# f29h85x_epg_regs register map
Vendor: Texas Instruments
Peripheral module from a debugger description file (folder C29).
Registers are 32-bit, read-write, no defined reset value unless marked. A register's access mark holds for its fields unless they carry their own. Offsets are as the file gives them; lines under a group give offsets from that group; [hi:lo] are bit positions; {n}, {i} and the like mark numbered series; 'fields as' and 'values as' point back to an identical list; <NAME> marks a mode.

## EPG_REGS — EPG Registers
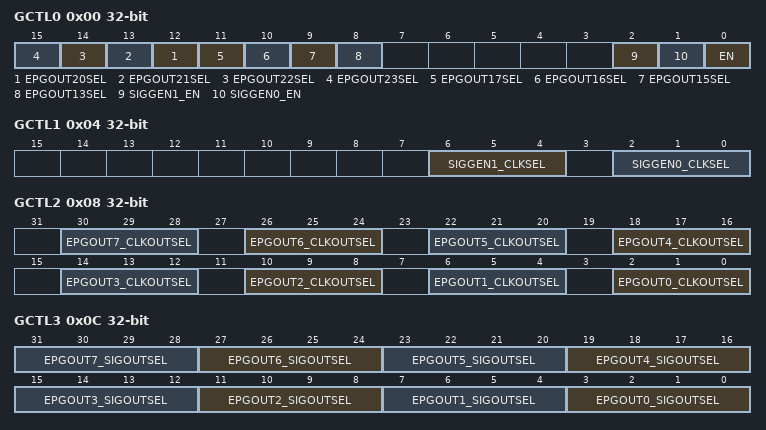
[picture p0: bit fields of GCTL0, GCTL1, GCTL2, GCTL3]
0x00 GCTL0 — EPG Global control register 0
  [n-8] EPGOUT{n}SEL (n=20..23) — EPG output {n} Clock/signal select
  [11] EPGOUT17SEL — EPG output 17 Clock/signal select
  [10] EPGOUT16SEL — EPG output 16 Clock/signal select
  [9] EPGOUT15SEL — EPG output 15 Clock/signal select
  [8] EPGOUT13SEL — EPG output 13 Clock/signal select
  [2] SIGGEN1_EN — Signal generator enable
  [1] SIGGEN0_EN — Signal generator enable
  [0] EN — Enable EPG
0x04 GCTL1 — EPG Global control register 1
  [6:4] SIGGEN1_CLKSEL — Clock source select of SIGGEN1
  [2:0] SIGGEN0_CLKSEL — Clock source select of SIGGEN0
0x08 GCTL2 — EPG Global control register 2
  [4n+2:4n] EPGOUT{n}_CLKOUTSEL (n=0..7) — Selects the clock signal source of EPG output {n}.
0x0C GCTL3 — EPG Global control register 3
  [4n+3:4n] EPGOUT{n}_SIGOUTSEL (n=0..7) — Selects the signal source of EPG output {n}.
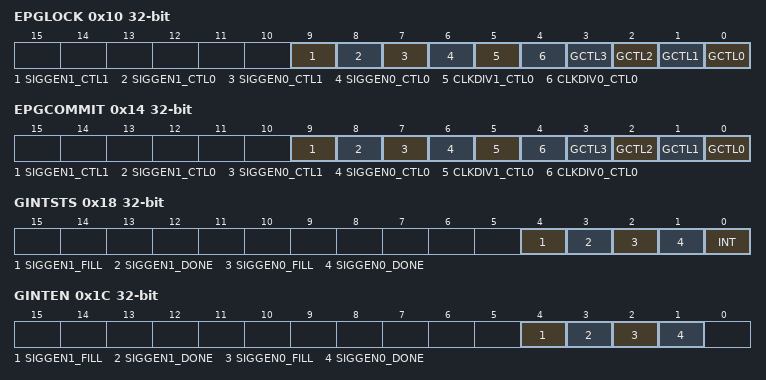
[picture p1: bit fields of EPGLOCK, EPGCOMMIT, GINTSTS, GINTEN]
0x10 EPGLOCK
  [9] SIGGEN1_CTL1 — SIGGEN1_CTL1 Lock bit
  [8] SIGGEN1_CTL0 — SIGGEN1_CTL0 Lock bit
  [7] SIGGEN0_CTL1 — SIGGEN0_CTL1 Lock bit
  [6] SIGGEN0_CTL0 — SIGGEN0_CTL0 Lock bit
  [5] CLKDIV1_CTL0 — CLKDIV1_CTL0 Lock bit
  [4] CLKDIV0_CTL0 — CLKDIV0_CTL0 Lock bit
  [n] GCTL{n} (n=0..3) — GCTL{n} Lock bit
0x14 EPGCOMMIT
  [9] SIGGEN1_CTL1 — SIGGEN1_CTL1 Commit bit
  [8] SIGGEN1_CTL0 — SIGGEN1_CTL0 Commit bit
  [7] SIGGEN0_CTL1 — SIGGEN0_CTL1 Commit bit
  [6] SIGGEN0_CTL0 — SIGGEN0_CTL0 Commit bit
  [5] CLKDIV1_CTL0 — CLKDIV1_CTL0 Commit bit
  [4] CLKDIV0_CTL0 — CLKDIV0_CTL0 Commit bit
  [n] GCTL{n} (n=0..3) — GCTL{n} Commit bit
0x18 GINTSTS ro — EPG Global interrupt status register.
  [4] SIGGEN1_FILL — SIGGEN1 data fill status
  [3] SIGGEN1_DONE — SIGGEN1 operation done status
  [2] SIGGEN0_FILL — SIGGEN0 data fill status
  [1] SIGGEN0_DONE — SIGGEN0 operation done status
  [0] INT — Global interrupt flag register
0x1C GINTEN — EPG Global interrupt enable register.
  [4] SIGGEN1_FILL — SIGGEN1 data fill interrupt enable
  [3] SIGGEN1_DONE — SIGGEN1 operation done interrupt enable
  [2] SIGGEN0_FILL — SIGGEN0 data fill interrupt enable
  [1] SIGGEN0_DONE — SIGGEN0 operation done interrupt enable
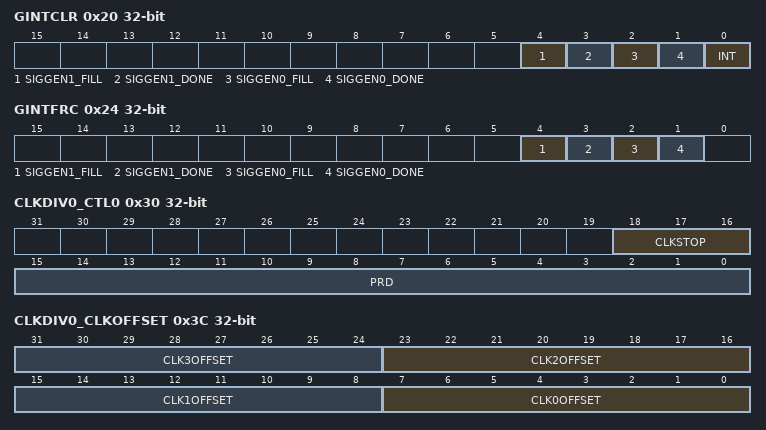
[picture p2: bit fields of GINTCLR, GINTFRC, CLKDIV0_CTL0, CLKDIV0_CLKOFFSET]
0x20 GINTCLR — EPG Global interrupt clear register.
  [4] SIGGEN1_FILL — SIGGEN1 data fill interrupt flag clear
  [3] SIGGEN1_DONE — SIGGEN0 data fill interrupt flag clear
  [2] SIGGEN0_FILL — SIGGEN0 data fill interrupt flag clear
  [1] SIGGEN0_DONE — SIGGEN0 operation done interrupt flag clear
  [0] INT — Global interrupt flag clear
0x24 GINTFRC — EPG Global interrupt force register.
  [4] SIGGEN1_FILL — SIGGEN1 data fill interrupt flag set
  [3] SIGGEN1_DONE — SIGGEN1 operation done interrupt flag set
  [2] SIGGEN0_FILL — SIGGEN0 data fill interrupt flag set
  [1] SIGGEN0_DONE — SIGGEN0 operation done interrupt flag set
0x30 CLKDIV0_CTL0 — Clock divider 0's control register 0
  [18:16] CLKSTOP — Clock Stop Configuration
  [15:0] PRD — Clock divider value
0x3C CLKDIV0_CLKOFFSET — Clock divider 0's clock offset value
  [8n+7:8n] CLK{n}OFFSET (n=0..3) — Clock output 0 offset delay value.
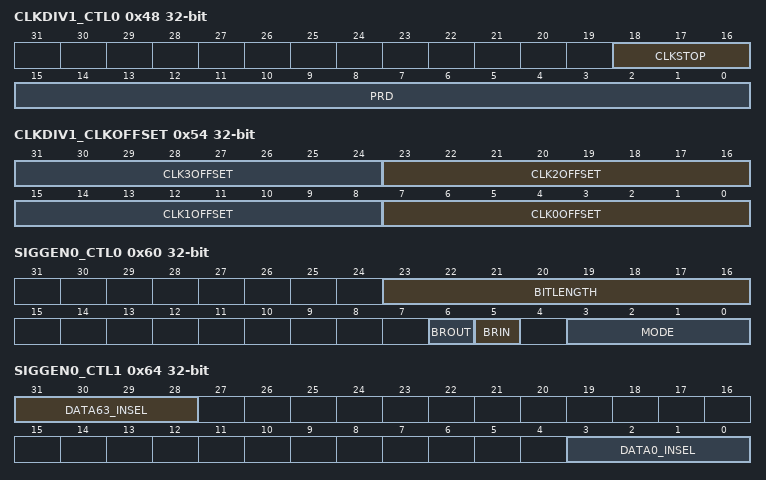
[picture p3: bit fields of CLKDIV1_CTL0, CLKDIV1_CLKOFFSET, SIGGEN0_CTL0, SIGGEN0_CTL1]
0x48 CLKDIV1_CTL0 — Clock divider 1's control register 0
  fields as CLKDIV0_CTL0
0x54 CLKDIV1_CLKOFFSET — Clock divider 1's clock offset value
  [8n+7:8n] CLK{n}OFFSET (n=0..3) — Clock output 0 offset delay value.
0x60 SIGGEN0_CTL0 — Signal generator 0's control register 0
  [23:16] BITLENGTH — Length of bit stream
  [6] BROUT — Reverse bits after transform
  [5] BRIN — Reverse bits before transform
  [3:0] MODE — Signal generator modes
0x64 SIGGEN0_CTL1 — Signal generator 0's control register 1
  [31:28] DATA63_INSEL — Select the source of DATA[63] bit.
  [3:0] DATA0_INSEL — Select the source of DATA[0] bit.
0x70 SIGGEN0_DATA0 — Signal generator 0's data register 0
  [31:0] SIGGEN_DATA0 — Data 0
0x74 SIGGEN0_DATA1 — Signal generator 0's data register 1
  [31:0] SIGGEN_DATA1 — Data 1
0x78 SIGGEN0_DATA0_ACTIVE ro — Signal generator 0's data active register 0
  [31:0] SIGEN_DATA0 — Data 0
0x7C SIGGEN0_DATA1_ACTIVE ro — Signal generator 0's data active register 1
  [31:0] SIGGEN_DATA1 — Data 1
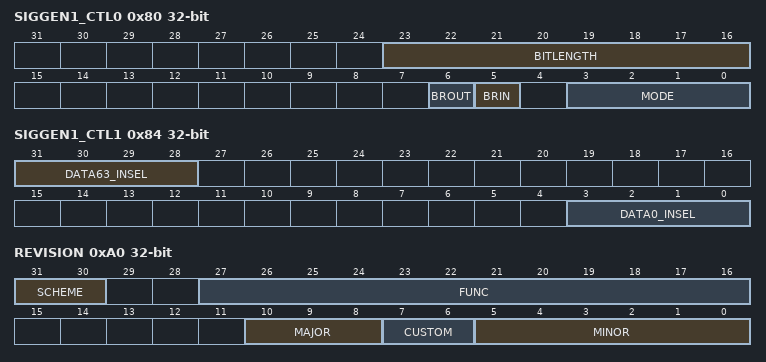
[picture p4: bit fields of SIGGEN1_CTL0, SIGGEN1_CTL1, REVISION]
0x80 SIGGEN1_CTL0 — Signal generator 1's control register 0
  fields as SIGGEN0_CTL0
0x84 SIGGEN1_CTL1 — Signal generator 1's control register 1
  fields as SIGGEN0_CTL1
0x90 SIGGEN1_DATA0 — Signal generator 1's data register 0
  [31:0] SIGEN_DATA0 — Data 0
0x94 SIGGEN1_DATA1 — Signal generator 1's data register 1
  [31:0] SIGGEN_DATA1 — Data 1
0x98 SIGGEN1_DATA0_ACTIVE ro — Signal generator 1's data active register 0
  [31:0] SIGEN_DATA0 — Data 0
0x9C SIGGEN1_DATA1_ACTIVE ro — Signal generator 1's data active register 1
  [31:0] SIGGEN_DATA1 — Data 1
0xA0 REVISION ro — IP Revision tie-off value
  [31:30] SCHEME — Defines Scheme for Module
  [27:16] FUNC — Functional Release Number
  [10:8] MAJOR — Major Revision Number
  [7:6] CUSTOM — Custom Module Number
  [5:0] MINOR — Minor Revision Number
